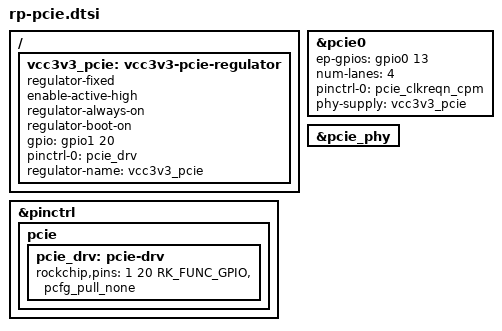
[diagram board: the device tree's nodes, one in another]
/**
 * rpdzkj configure for pcie
 *
 * Only pcie related configuration is placed here.
 */
 
/ {
        vcc3v3_pcie: vcc3v3-pcie-regulator {
                compatible = "regulator-fixed";
                enable-active-high;
                regulator-always-on;
                regulator-boot-on;
                gpio = <&gpio1 20 GPIO_ACTIVE_HIGH>;
                pinctrl-names = "default";
                pinctrl-0 = <&pcie_drv>;
                regulator-name = "vcc3v3_pcie";
        };
};

&pcie0 {
        ep-gpios = <&gpio0 13 GPIO_ACTIVE_HIGH>;
        num-lanes = <4>;
        pinctrl-names = "default";
        pinctrl-0 = <&pcie_clkreqn_cpm>;
        phy-supply = <&vcc3v3_pcie>;
        status = "okay";
};

&pcie_phy {
        status = "okay";
};

&pinctrl {
        pcie {
                pcie_drv: pcie-drv {
                        rockchip,pins =
                                <1 20 RK_FUNC_GPIO &pcfg_pull_none>;
                };
        };
};
